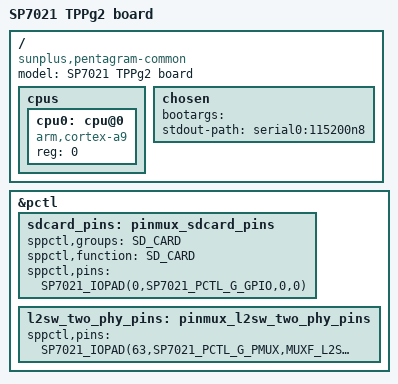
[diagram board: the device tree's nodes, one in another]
/*
 * Sunplus Pentagram board DTS
 *
 * SPDX-License-Identifier:	GPL-2.0+
 */
/dts-v1/;
#include "pentagram-sp70xx.dtsi"

/ {
	model = "SP7021 TPPg2 board";
	compatible = "sunplus,pentagram-common", "sunplus,pentagram";

	#address-cells = <1>;
	#size-cells = <1>;

	cpus {
		#address-cells = <1>;
		#size-cells = <0>;

		cpu0: cpu@0 {
			compatible = "arm,cortex-a9";
			device_type = "cpu";
			reg = <0>;
		};
	};

	chosen {
		bootargs = "";
		stdout-path = "serial0:115200n8";
	};


};

&pctl {
	sdcard_pins: pinmux_sdcard_pins {
		sppctl,groups = "SD_CARD";
		sppctl,function = "SD_CARD";
		sppctl,pins = <	SP7021_IOPAD(0,SP7021_PCTL_G_GPIO,0,0)	>;
	};
	l2sw_two_phy_pins: pinmux_l2sw_two_phy_pins {
		sppctl,pins = <
			SP7021_IOPAD(63,SP7021_PCTL_G_PMUX,MUXF_L2SW_CLK_OUT,0)
			SP7021_IOPAD(71,SP7021_PCTL_G_PMUX,MUXF_L2SW_MAC_SMI_MDC,0)
			SP7021_IOPAD(64,SP7021_PCTL_G_PMUX,MUXF_L2SW_MAC_SMI_MDIO,0)

			SP7021_IOPAD(62,SP7021_PCTL_G_PMUX,MUXF_L2SW_P0_MAC_RMII_TXEN,0)
			SP7021_IOPAD(61,SP7021_PCTL_G_PMUX,MUXF_L2SW_P0_MAC_RMII_TXD0,0)
			SP7021_IOPAD(60,SP7021_PCTL_G_PMUX,MUXF_L2SW_P0_MAC_RMII_TXD1,0)
			SP7021_IOPAD(59,SP7021_PCTL_G_PMUX,MUXF_L2SW_P0_MAC_RMII_CRSDV,0)
			SP7021_IOPAD(58,SP7021_PCTL_G_PMUX,MUXF_L2SW_P0_MAC_RMII_RXD0,0)
			SP7021_IOPAD(57,SP7021_PCTL_G_PMUX,MUXF_L2SW_P0_MAC_RMII_RXD1,0)

			SP7021_IOPAD(55,SP7021_PCTL_G_PMUX,MUXF_L2SW_P1_MAC_RMII_TXEN,0)
			SP7021_IOPAD(54,SP7021_PCTL_G_PMUX,MUXF_L2SW_P1_MAC_RMII_TXD0,0)
			SP7021_IOPAD(53,SP7021_PCTL_G_PMUX,MUXF_L2SW_P1_MAC_RMII_TXD1,0)
			SP7021_IOPAD(52,SP7021_PCTL_G_PMUX,MUXF_L2SW_P1_MAC_RMII_CRSDV,0)
			SP7021_IOPAD(51,SP7021_PCTL_G_PMUX,MUXF_L2SW_P1_MAC_RMII_RXD0,0)
			SP7021_IOPAD(50,SP7021_PCTL_G_PMUX,MUXF_L2SW_P1_MAC_RMII_RXD1,0)
		>;
	};
};
